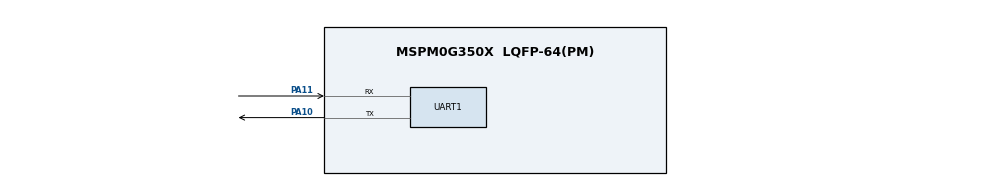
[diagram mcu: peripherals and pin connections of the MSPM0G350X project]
/**
 * @cliArgs --device "MSPM0G350X" --package "LQFP-64(PM)" --part "Default" --product "mspm0_sdk@2.01.00.03"
 * @versions {"tool":"1.20.0+3587"}
 */

/**
 * Import the modules used in this configuration.
 */
const SYSCTL = scripting.addModule("/ti/driverlib/SYSCTL");
const UART   = scripting.addModule("/ti/driverlib/UART", {}, false);
const UART1  = UART.addInstance();

/**
 * Write custom configuration values to the imported modules.
 */
const gate7  = system.clockTree["MFCLKGATE"];
gate7.enable = true;

SYSCTL.forceDefaultClkConfig = true;
SYSCTL.clockTreeEn           = true;

const Board = scripting.addModule("/ti/driverlib/Board", {}, false);

UART1.$name                    = "UART_0";
UART1.enabledInterrupts        = ["RX"];
UART1.uartClkSrc               = "MFCLK";
UART1.peripheral.rxPin.$assign = "PA11";
UART1.peripheral.txPin.$assign = "PA10";
UART1.txPinConfig.$name        = "ti_driverlib_gpio_GPIOPinGeneric0";
UART1.rxPinConfig.$name        = "ti_driverlib_gpio_GPIOPinGeneric1";

/**
 * Pinmux solution for unlocked pins/peripherals. This ensures that minor changes to the automatic solver in a future
 * version of the tool will not impact the pinmux you originally saw.  These lines can be completely deleted in order to
 * re-solve from scratch.
 */
Board.peripheral.$suggestSolution          = "DEBUGSS";
Board.peripheral.swclkPin.$suggestSolution = "PA20";
Board.peripheral.swdioPin.$suggestSolution = "PA19";
UART1.peripheral.$suggestSolution          = "UART0";
